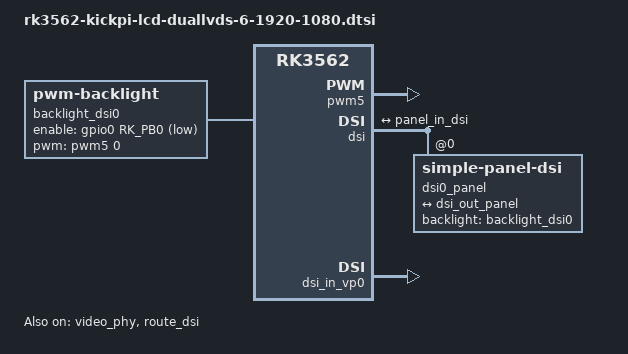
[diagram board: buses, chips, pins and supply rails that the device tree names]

/ {
	backlight_dsi0: backlight-dsi0 {
		compatible = "pwm-backlight";
		pwms = <&pwm5 0 25000 0>;
		brightness-levels = <
			  0  20  20  21  21  22  22  23
			 23  24  24  25  25  26  26  27
			 27  28  28  29  29  30  30  31
			 31  32  32  33  33  34  34  35
			 35  36  36  37  37  38  38  39
			 40  41  42  43  44  45  46  47
			 48  49  50  51  52  53  54  55
			 56  57  58  59  60  61  62  63
			 64  65  66  67  68  69  70  71
			 72  73  74  75  76  77  78  79
			 80  81  82  83  84  85  86  87
			 88  89  90  91  92  93  94  95
			 96  97  98  99 100 101 102 103
			104 105 106 107 108 109 110 111
			112 113 114 115 116 117 118 119
			120 121 122 123 124 125 126 127
			128 129 130 131 132 133 134 135
			136 137 138 139 140 141 142 143
			144 145 146 147 148 149 150 151
			152 153 154 155 156 157 158 159
			160 161 162 163 164 165 166 167
			168 169 170 171 172 173 174 175
			176 177 178 179 180 181 182 183
			184 185 186 187 188 189 190 191
			192 193 194 195 196 197 198 199
			200 201 202 203 204 205 206 207
			208 209 210 211 212 213 214 215
			216 217 218 219 220 221 222 223
			224 225 226 227 228 229 230 231
			232 233 234 235 236 237 238 239
			240 241 242 243 244 245 246 247
			248 249 250 251 252 253 254 255
		>;
		default-brightness-level = <200>;
		enable-gpios = <&gpio0 RK_PB0 GPIO_ACTIVE_LOW>;
	};
};

&pwm5 {
	status = "okay";
	pinctrl-0 = <&pwm5m0_pins>;
};

/*
 * video_phy0 needs to be enabled
 * when dsi0 is enabled
 */
&dsi {
	status = "okay";
	//rockchip,lane-rate = <1000>;
	dsi0_panel: panel@0 {
		status = "okay";
		compatible = "simple-panel-dsi";
		reg = <0>;
		backlight = <&backlight_dsi0>;

		reset-delay-ms = <30>;
		enable-delay-ms = <30>;
		prepare-delay-ms = <30>;
		init-delay-ms = <30>;
		unprepare-delay-ms = <30>;
		disable-delay-ms = <30>;

		dsi,flags = <(MIPI_DSI_MODE_VIDEO | MIPI_DSI_MODE_VIDEO_BURST |
			MIPI_DSI_MODE_LPM | MIPI_DSI_MODE_EOT_PACKET)>;
		dsi,format = <MIPI_DSI_FMT_RGB888>;
		dsi,lanes  = <4>;
		panel-init-sequence = [
			29 00 03 FF 3A 5A
			29 00 03 00 0F 01
			29 00 03 2C 05 05
			29 00 03 D8 10 01
			29 00 03 12 0F 00
			29 00 03 0C 05 03
			29 00 03 0A 05 80
			29 00 03 25 0F 13
			29 00 03 21 0F 04
			29 00 03 06 10 1C
			29 00 03 07 10 00
			29 00 03 08 10 00
			29 00 03 09 10 00
			29 00 03 01 10 03
			29 00 03 03 10 00
			29 00 03 00 10 18
			29 00 03 01 0F 40
			29 00 03 02 0F 00
			29 00 03 00 2C 93 //83, port0/1 exchange
			29 00 03 02 2C 01
			29 00 03 1C 05 03
			29 00 03 1D 05 C0
			29 00 03 0B 05 10
			29 00 03 24 05 02
			29 00 03 28 05 00
			29 00 03 81 10 38
			29 00 03 82 10 04
			29 00 03 18 0F 00
			29 00 03 2B 05 40
			29 00 03 83 10 C0
			29 00 03 84 10 03
			29 00 03 85 10 4C
			29 00 03 86 10 04
			29 00 03 87 10 02
			29 00 03 88 10 00
			29 00 03 89 10 02
			29 00 03 8A 10 00
			29 00 03 8B 10 88
			29 00 03 8C 10 00
			29 00 03 8D 10 0A
			29 00 03 8E 10 05
			29 00 03 8F 10 1E
			29 00 03 80 10 04
			29 14 03 22 10 DB
			29 14 03 22 10 FB
			29 14 03 0D 10 01
		];

		panel-exit-sequence = [
			05 00 01 28
			05 78 01 10
		];

		disp_timings0: display-timings {
			native-mode = <&dsi0_timing0>;
			dsi0_timing0: timing0 {
				clock-frequency = <148500000>;
				hactive = <1920>;
				vactive = <1080>;
				hback-porch = <120>;
				hfront-porch = <120>;
				vback-porch = <15>;
				vfront-porch = <15>;
				hsync-len = <40>;
				vsync-len = <15>;
				hsync-active = <0>;
				vsync-active = <0>;
				de-active = <0>;
				pixelclk-active = <0>;
			};
		};

		ports {
			#address-cells = <1>;
			#size-cells = <0>;

			port@0 {
				reg = <0>;
				panel_in_dsi: endpoint {
					remote-endpoint = <&dsi_out_panel>;
				};
			};
		};
	};

	ports {
		#address-cells = <1>;
		#size-cells = <0>;

		port@1 {
			reg = <1>;
			dsi_out_panel: endpoint {
				remote-endpoint = <&panel_in_dsi>;
			};
		};
	};
};

&dsi_in_vp0 {
	status = "okay";
};

&video_phy {
	status = "okay";
};

&route_dsi {
	status = "okay";
	connect = <&vp0_out_dsi>;
};

